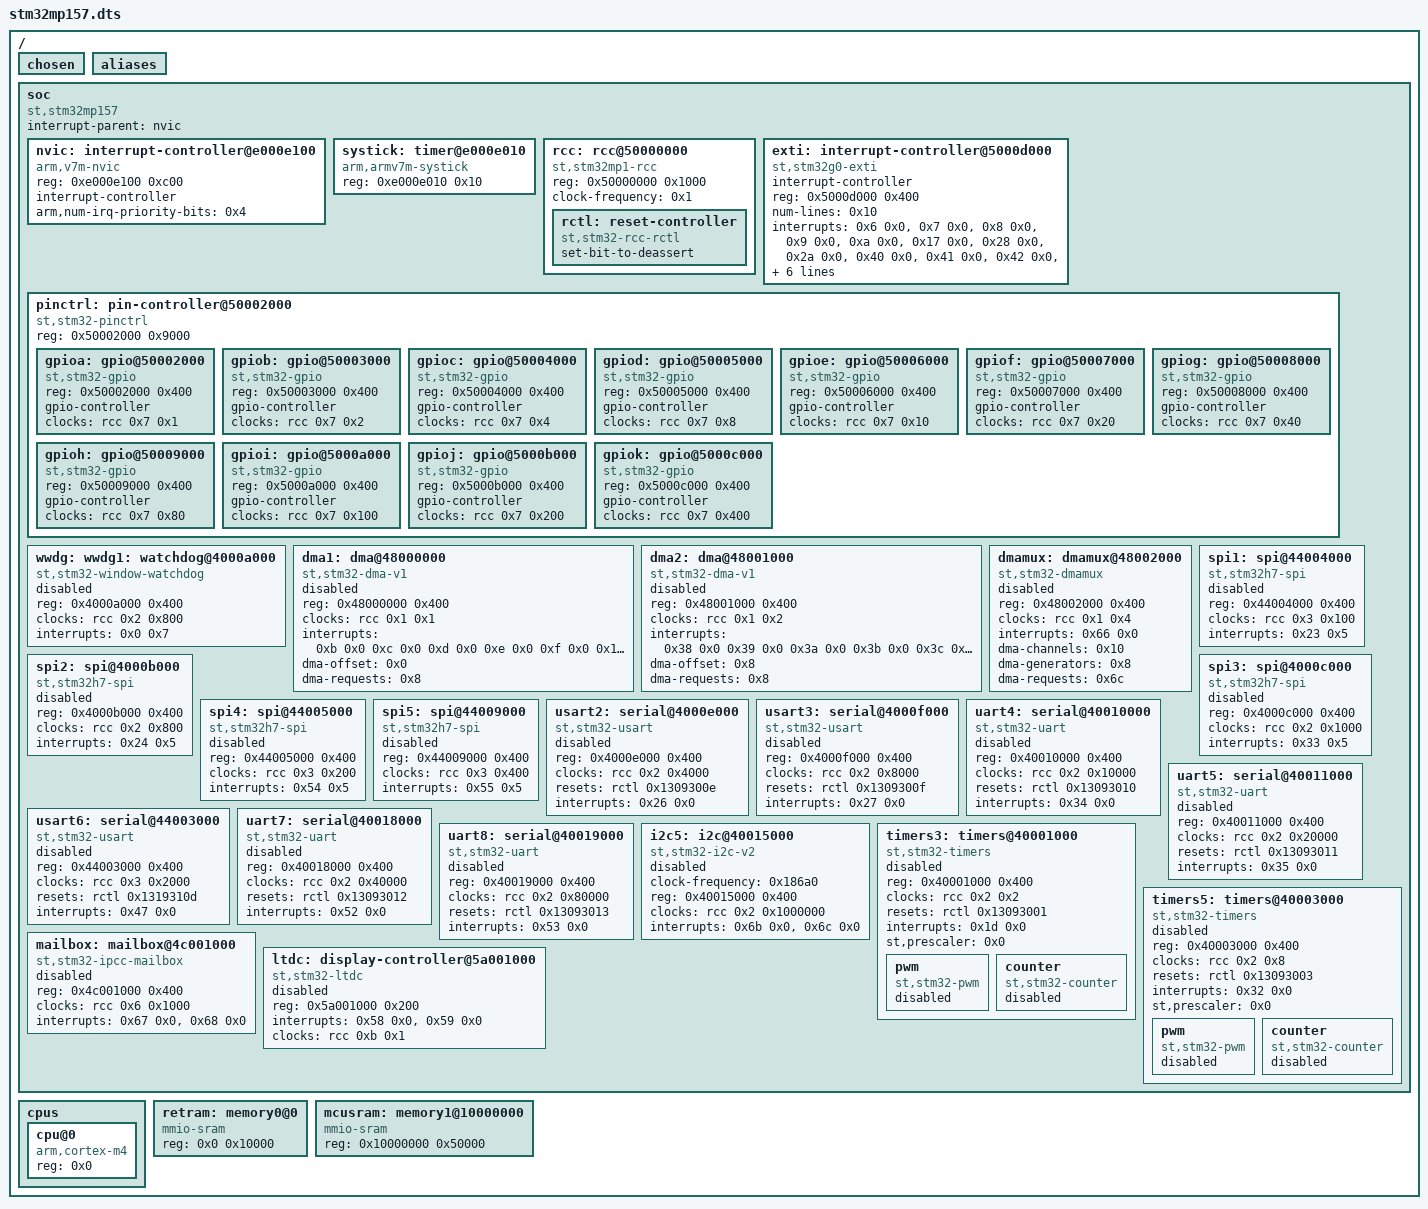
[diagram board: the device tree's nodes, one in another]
/dts-v1/;

/ {
	#address-cells = < 0x1 >;
	#size-cells = < 0x1 >;
	chosen {
	};
	aliases {
	};
	soc {
		#address-cells = < 0x1 >;
		#size-cells = < 0x1 >;
		compatible = "st,stm32mp157", "st,stm32mp1", "simple-bus";
		interrupt-parent = < &nvic >;
		ranges;
		nvic: interrupt-controller@e000e100 {
			#address-cells = < 0x1 >;
			compatible = "arm,v7m-nvic";
			reg = < 0xe000e100 0xc00 >;
			interrupt-controller;
			#interrupt-cells = < 0x2 >;
			arm,num-irq-priority-bits = < 0x4 >;
			phandle = < 0x1 >;
		};
		systick: timer@e000e010 {
			compatible = "arm,armv7m-systick";
			reg = < 0xe000e010 0x10 >;
		};
		rcc: rcc@50000000 {
			compatible = "st,stm32mp1-rcc";
			reg = < 0x50000000 0x1000 >;
			#clock-cells = < 0x2 >;
			clock-frequency = < 0x1 >;
			phandle = < 0x2 >;
			rctl: reset-controller {
				compatible = "st,stm32-rcc-rctl";
				#reset-cells = < 0x1 >;
				set-bit-to-deassert;
				phandle = < 0x3 >;
			};
		};
		exti: interrupt-controller@5000d000 {
			compatible = "st,stm32g0-exti", "st,stm32-exti";
			interrupt-controller;
			#interrupt-cells = < 0x1 >;
			#address-cells = < 0x1 >;
			reg = < 0x5000d000 0x400 >;
			num-lines = < 0x10 >;
			interrupts = < 0x6 0x0 >, < 0x7 0x0 >, < 0x8 0x0 >, < 0x9 0x0 >, < 0xa 0x0 >, < 0x17 0x0 >, < 0x28 0x0 >, < 0x2a 0x0 >, < 0x40 0x0 >, < 0x41 0x0 >, < 0x42 0x0 >, < 0x43 0x0 >, < 0x4c 0x0 >, < 0x4d 0x0 >, < 0x79 0x0 >, < 0x7f 0x0 >;
			interrupt-names = "line0", "line1", "line2", "line3", "line4", "line5", "line6", "line7", "line8", "line9", "line10", "line11", "line12", "line13", "line14", "line15";
			line-ranges = < 0x0 0x1 >, < 0x1 0x1 >, < 0x2 0x1 >, < 0x3 0x1 >, < 0x4 0x1 >, < 0x5 0x1 >, < 0x6 0x1 >, < 0x7 0x1 >, < 0x8 0x1 >, < 0x9 0x1 >, < 0xa 0x1 >, < 0xb 0x1 >, < 0xc 0x1 >, < 0xd 0x1 >, < 0xe 0x1 >, < 0xf 0x1 >;
		};
		pinctrl: pin-controller@50002000 {
			compatible = "st,stm32-pinctrl";
			reg = < 0x50002000 0x9000 >;
			#address-cells = < 0x1 >;
			#size-cells = < 0x1 >;
			gpioa: gpio@50002000 {
				compatible = "st,stm32-gpio";
				reg = < 0x50002000 0x400 >;
				gpio-controller;
				#gpio-cells = < 0x2 >;
				clocks = < &rcc 0x7 0x1 >;
			};
			gpiob: gpio@50003000 {
				compatible = "st,stm32-gpio";
				reg = < 0x50003000 0x400 >;
				gpio-controller;
				#gpio-cells = < 0x2 >;
				clocks = < &rcc 0x7 0x2 >;
			};
			gpioc: gpio@50004000 {
				compatible = "st,stm32-gpio";
				reg = < 0x50004000 0x400 >;
				gpio-controller;
				#gpio-cells = < 0x2 >;
				clocks = < &rcc 0x7 0x4 >;
			};
			gpiod: gpio@50005000 {
				compatible = "st,stm32-gpio";
				reg = < 0x50005000 0x400 >;
				gpio-controller;
				#gpio-cells = < 0x2 >;
				clocks = < &rcc 0x7 0x8 >;
			};
			gpioe: gpio@50006000 {
				compatible = "st,stm32-gpio";
				reg = < 0x50006000 0x400 >;
				gpio-controller;
				#gpio-cells = < 0x2 >;
				clocks = < &rcc 0x7 0x10 >;
			};
			gpiof: gpio@50007000 {
				compatible = "st,stm32-gpio";
				reg = < 0x50007000 0x400 >;
				gpio-controller;
				#gpio-cells = < 0x2 >;
				clocks = < &rcc 0x7 0x20 >;
			};
			gpiog: gpio@50008000 {
				compatible = "st,stm32-gpio";
				reg = < 0x50008000 0x400 >;
				gpio-controller;
				#gpio-cells = < 0x2 >;
				clocks = < &rcc 0x7 0x40 >;
			};
			gpioh: gpio@50009000 {
				compatible = "st,stm32-gpio";
				reg = < 0x50009000 0x400 >;
				gpio-controller;
				#gpio-cells = < 0x2 >;
				clocks = < &rcc 0x7 0x80 >;
			};
			gpioi: gpio@5000a000 {
				compatible = "st,stm32-gpio";
				reg = < 0x5000a000 0x400 >;
				gpio-controller;
				#gpio-cells = < 0x2 >;
				clocks = < &rcc 0x7 0x100 >;
			};
			gpioj: gpio@5000b000 {
				compatible = "st,stm32-gpio";
				reg = < 0x5000b000 0x400 >;
				gpio-controller;
				#gpio-cells = < 0x2 >;
				clocks = < &rcc 0x7 0x200 >;
			};
			gpiok: gpio@5000c000 {
				compatible = "st,stm32-gpio";
				reg = < 0x5000c000 0x400 >;
				gpio-controller;
				#gpio-cells = < 0x2 >;
				clocks = < &rcc 0x7 0x400 >;
			};
		};
		wwdg: wwdg1: watchdog@4000a000 {
			compatible = "st,stm32-window-watchdog";
			reg = < 0x4000a000 0x400 >;
			clocks = < &rcc 0x2 0x800 >;
			interrupts = < 0x0 0x7 >;
			status = "disabled";
		};
		dma1: dma@48000000 {
			compatible = "st,stm32-dma-v1";
			#dma-cells = < 0x4 >;
			reg = < 0x48000000 0x400 >;
			clocks = < &rcc 0x1 0x1 >;
			interrupts = < 0xb 0x0 0xc 0x0 0xd 0x0 0xe 0x0 0xf 0x0 0x10 0x0 0x11 0x0 0x2f 0x0 >;
			dma-offset = < 0x0 >;
			dma-requests = < 0x8 >;
			status = "disabled";
		};
		dma2: dma@48001000 {
			compatible = "st,stm32-dma-v1";
			#dma-cells = < 0x4 >;
			reg = < 0x48001000 0x400 >;
			clocks = < &rcc 0x1 0x2 >;
			interrupts = < 0x38 0x0 0x39 0x0 0x3a 0x0 0x3b 0x0 0x3c 0x0 0x44 0x0 0x45 0x0 0x46 0x0 >;
			dma-offset = < 0x8 >;
			dma-requests = < 0x8 >;
			status = "disabled";
		};
		dmamux: dmamux@48002000 {
			compatible = "st,stm32-dmamux";
			#dma-cells = < 0x3 >;
			reg = < 0x48002000 0x400 >;
			clocks = < &rcc 0x1 0x4 >;
			interrupts = < 0x66 0x0 >;
			dma-channels = < 0x10 >;
			dma-generators = < 0x8 >;
			dma-requests = < 0x6c >;
			status = "disabled";
		};
		spi1: spi@44004000 {
			compatible = "st,stm32h7-spi", "st,stm32-spi-fifo", "st,stm32-spi";
			reg = < 0x44004000 0x400 >;
			#address-cells = < 0x1 >;
			#size-cells = < 0x0 >;
			clocks = < &rcc 0x3 0x100 >;
			interrupts = < 0x23 0x5 >;
			status = "disabled";
		};
		spi2: spi@4000b000 {
			compatible = "st,stm32h7-spi", "st,stm32-spi-fifo", "st,stm32-spi";
			reg = < 0x4000b000 0x400 >;
			#address-cells = < 0x1 >;
			#size-cells = < 0x0 >;
			clocks = < &rcc 0x2 0x800 >;
			interrupts = < 0x24 0x5 >;
			status = "disabled";
		};
		spi3: spi@4000c000 {
			compatible = "st,stm32h7-spi", "st,stm32-spi-fifo", "st,stm32-spi";
			reg = < 0x4000c000 0x400 >;
			#address-cells = < 0x1 >;
			#size-cells = < 0x0 >;
			clocks = < &rcc 0x2 0x1000 >;
			interrupts = < 0x33 0x5 >;
			status = "disabled";
		};
		spi4: spi@44005000 {
			compatible = "st,stm32h7-spi", "st,stm32-spi-fifo", "st,stm32-spi";
			reg = < 0x44005000 0x400 >;
			#address-cells = < 0x1 >;
			#size-cells = < 0x0 >;
			clocks = < &rcc 0x3 0x200 >;
			interrupts = < 0x54 0x5 >;
			status = "disabled";
		};
		spi5: spi@44009000 {
			compatible = "st,stm32h7-spi", "st,stm32-spi-fifo", "st,stm32-spi";
			reg = < 0x44009000 0x400 >;
			#address-cells = < 0x1 >;
			#size-cells = < 0x0 >;
			clocks = < &rcc 0x3 0x400 >;
			interrupts = < 0x55 0x5 >;
			status = "disabled";
		};
		usart2: serial@4000e000 {
			compatible = "st,stm32-usart", "st,stm32-uart";
			reg = < 0x4000e000 0x400 >;
			clocks = < &rcc 0x2 0x4000 >;
			resets = < &rctl 0x1309300e >;
			interrupts = < 0x26 0x0 >;
			status = "disabled";
		};
		usart3: serial@4000f000 {
			compatible = "st,stm32-usart", "st,stm32-uart";
			reg = < 0x4000f000 0x400 >;
			clocks = < &rcc 0x2 0x8000 >;
			resets = < &rctl 0x1309300f >;
			interrupts = < 0x27 0x0 >;
			status = "disabled";
		};
		uart4: serial@40010000 {
			compatible = "st,stm32-uart";
			reg = < 0x40010000 0x400 >;
			clocks = < &rcc 0x2 0x10000 >;
			resets = < &rctl 0x13093010 >;
			interrupts = < 0x34 0x0 >;
			status = "disabled";
		};
		uart5: serial@40011000 {
			compatible = "st,stm32-uart";
			reg = < 0x40011000 0x400 >;
			clocks = < &rcc 0x2 0x20000 >;
			resets = < &rctl 0x13093011 >;
			interrupts = < 0x35 0x0 >;
			status = "disabled";
		};
		usart6: serial@44003000 {
			compatible = "st,stm32-usart", "st,stm32-uart";
			reg = < 0x44003000 0x400 >;
			clocks = < &rcc 0x3 0x2000 >;
			resets = < &rctl 0x1319310d >;
			interrupts = < 0x47 0x0 >;
			status = "disabled";
		};
		uart7: serial@40018000 {
			compatible = "st,stm32-uart";
			reg = < 0x40018000 0x400 >;
			clocks = < &rcc 0x2 0x40000 >;
			resets = < &rctl 0x13093012 >;
			interrupts = < 0x52 0x0 >;
			status = "disabled";
		};
		uart8: serial@40019000 {
			compatible = "st,stm32-uart";
			reg = < 0x40019000 0x400 >;
			clocks = < &rcc 0x2 0x80000 >;
			resets = < &rctl 0x13093013 >;
			interrupts = < 0x53 0x0 >;
			status = "disabled";
		};
		i2c5: i2c@40015000 {
			compatible = "st,stm32-i2c-v2";
			clock-frequency = < 0x186a0 >;
			reg = < 0x40015000 0x400 >;
			#address-cells = < 0x1 >;
			#size-cells = < 0x0 >;
			clocks = < &rcc 0x2 0x1000000 >;
			interrupt-names = "event", "error";
			interrupts = < 0x6b 0x0 >, < 0x6c 0x0 >;
			status = "disabled";
		};
		timers3: timers@40001000 {
			compatible = "st,stm32-timers";
			reg = < 0x40001000 0x400 >;
			clocks = < &rcc 0x2 0x2 >;
			resets = < &rctl 0x13093001 >;
			interrupts = < 0x1d 0x0 >;
			interrupt-names = "global";
			st,prescaler = < 0x0 >;
			status = "disabled";
			pwm {
				compatible = "st,stm32-pwm";
				status = "disabled";
				#pwm-cells = < 0x3 >;
			};
			counter {
				compatible = "st,stm32-counter";
				status = "disabled";
			};
		};
		timers5: timers@40003000 {
			compatible = "st,stm32-timers";
			reg = < 0x40003000 0x400 >;
			clocks = < &rcc 0x2 0x8 >;
			resets = < &rctl 0x13093003 >;
			interrupts = < 0x32 0x0 >;
			interrupt-names = "global";
			st,prescaler = < 0x0 >;
			status = "disabled";
			pwm {
				compatible = "st,stm32-pwm";
				status = "disabled";
				#pwm-cells = < 0x3 >;
			};
			counter {
				compatible = "st,stm32-counter";
				status = "disabled";
			};
		};
		mailbox: mailbox@4c001000 {
			compatible = "st,stm32-ipcc-mailbox";
			reg = < 0x4c001000 0x400 >;
			clocks = < &rcc 0x6 0x1000 >;
			interrupts = < 0x67 0x0 >, < 0x68 0x0 >;
			interrupt-names = "rxo", "txf";
			status = "disabled";
		};
		ltdc: display-controller@5a001000 {
			compatible = "st,stm32-ltdc";
			reg = < 0x5a001000 0x200 >;
			interrupts = < 0x58 0x0 >, < 0x59 0x0 >;
			interrupt-names = "ltdc", "ltdc_er";
			clocks = < &rcc 0xb 0x1 >;
			status = "disabled";
		};
	};
	cpus {
		#address-cells = < 0x1 >;
		#size-cells = < 0x0 >;
		cpu@0 {
			device_type = "cpu";
			compatible = "arm,cortex-m4";
			reg = < 0x0 >;
		};
	};
	retram: memory0@0 {
		compatible = "mmio-sram";
		reg = < 0x0 0x10000 >;
	};
	mcusram: memory1@10000000 {
		compatible = "mmio-sram";
		reg = < 0x10000000 0x50000 >;
	};
};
